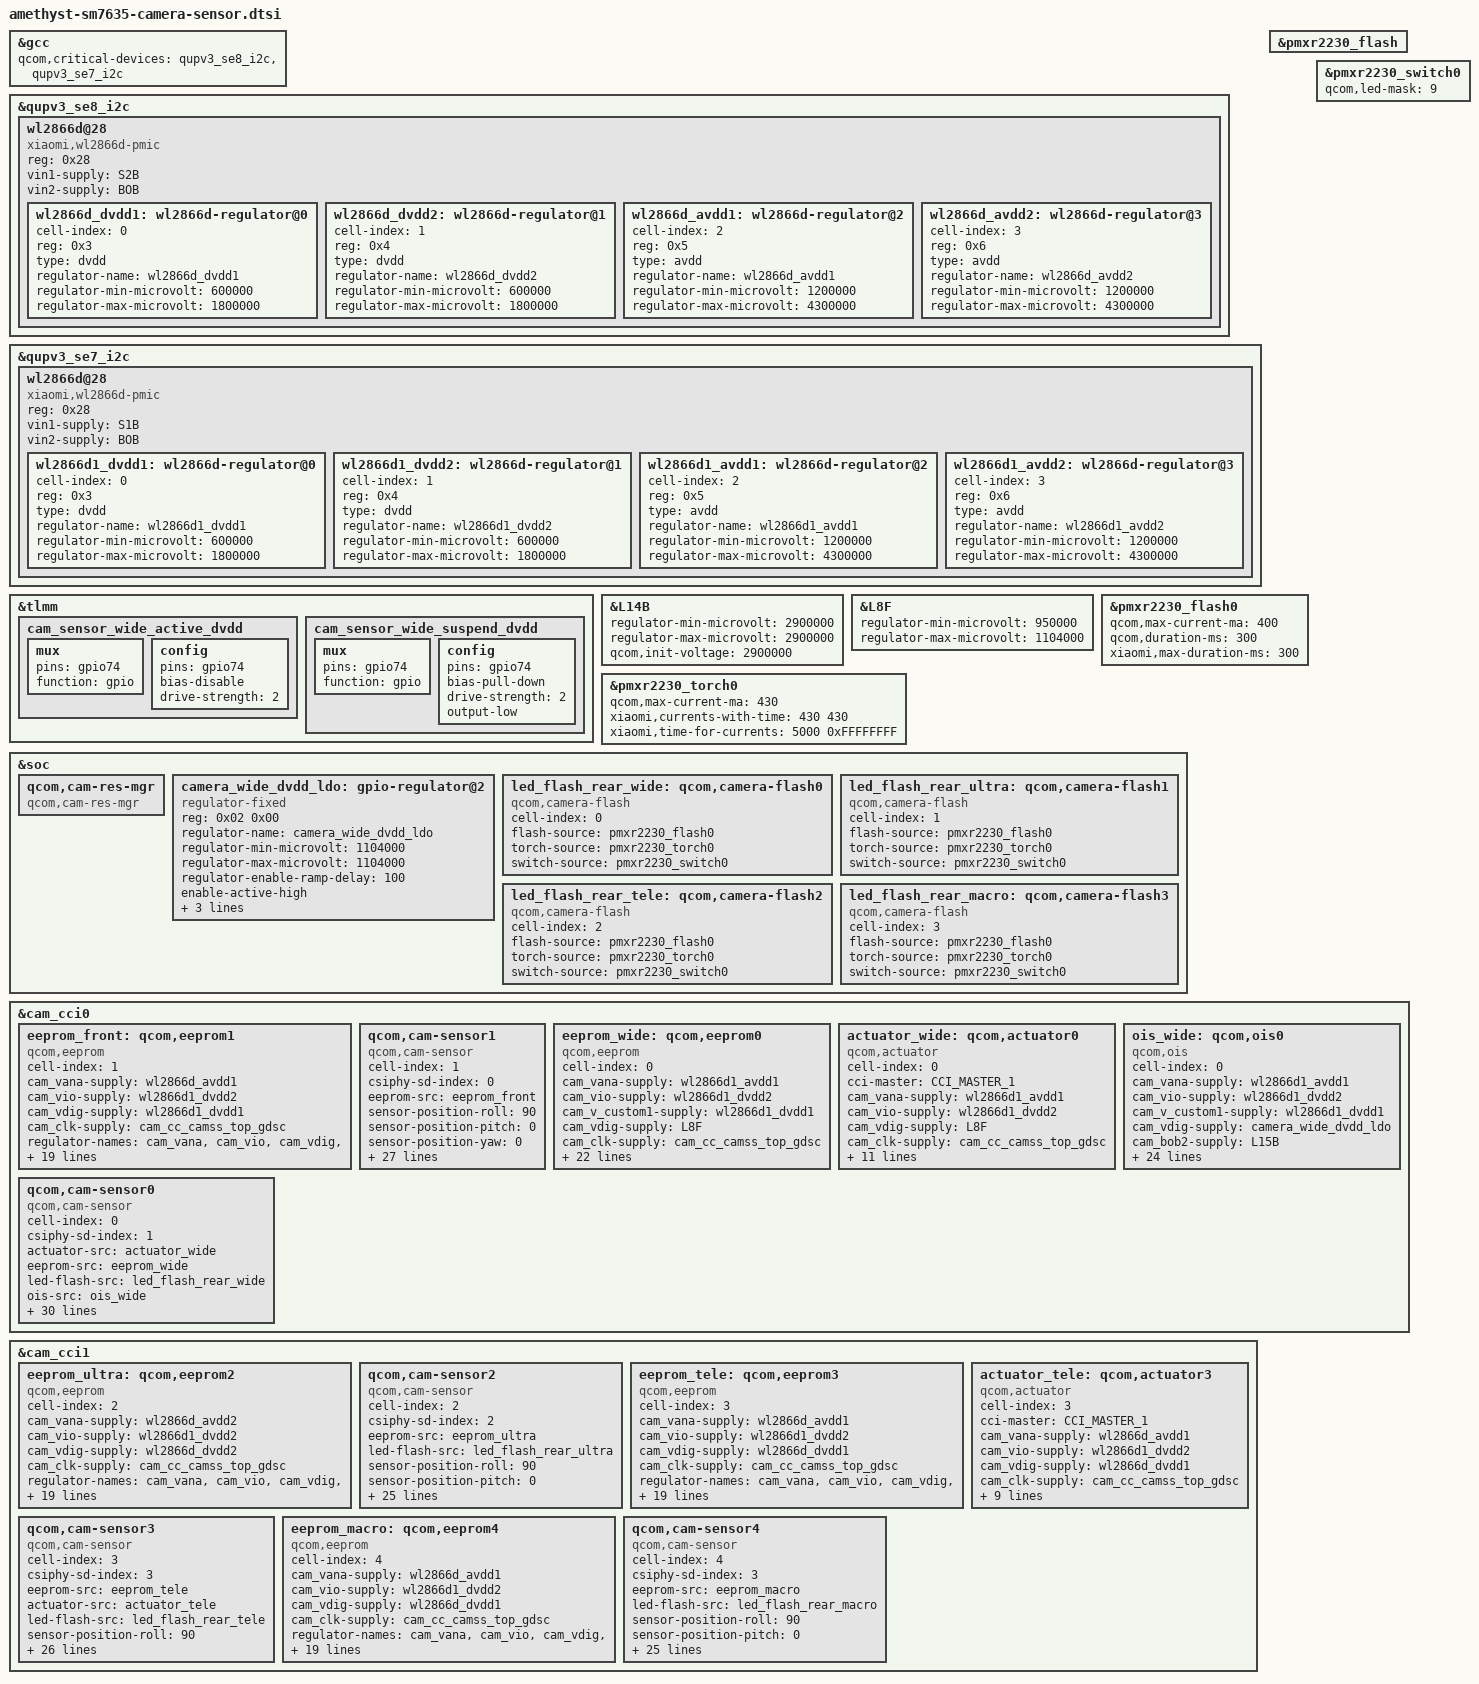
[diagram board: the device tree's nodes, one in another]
#include <dt-bindings/msm-camera.h>
&gcc {
	qcom,critical-devices = <&qupv3_se8_i2c &qupv3_se7_i2c>;
};
//bob
&qupv3_se8_i2c {
	#address-cells = <1>;
	#size-cells = <0>;
	status = "ok";

	wl2866d@28 {
		compatible = "xiaomi,wl2866d-pmic";
		reg = <0x28>;
		vin1-supply = <&S2B>;
		vin2-supply = <&BOB>;

		wl2866d_dvdd1: wl2866d-regulator@0 {
			cell-index = <0>;
			reg = /bits/ 8 <0x3>;
			type = "dvdd";
			regulator-name = "wl2866d_dvdd1";
			regulator-min-microvolt = <600000>;
			regulator-max-microvolt = <1800000>;
		};

		wl2866d_dvdd2: wl2866d-regulator@1 {
			cell-index = <1>;
			reg = /bits/ 8 <0x4>;
			type = "dvdd";
			regulator-name = "wl2866d_dvdd2";
			regulator-min-microvolt = <600000>;
			regulator-max-microvolt = <1800000>;
		};

		wl2866d_avdd1: wl2866d-regulator@2 {
			cell-index = <2>;
			reg = /bits/ 8 <0x5>;
			type = "avdd";
			regulator-name = "wl2866d_avdd1";
			regulator-min-microvolt = <1200000>;
			regulator-max-microvolt = <4300000>;
		};

		wl2866d_avdd2: wl2866d-regulator@3 {
			cell-index = <3>;
			reg = /bits/ 8 <0x6>;
			type = "avdd";
			regulator-name = "wl2866d_avdd2";
			regulator-min-microvolt = <1200000>;
			regulator-max-microvolt = <4300000>;
		};
	};
};
//hap
&qupv3_se7_i2c {
	#address-cells = <1>;
	#size-cells = <0>;
	status = "ok";

	wl2866d@28 {
		compatible = "xiaomi,wl2866d-pmic";
		reg = <0x28>;
		vin1-supply = <&S1B>;
		vin2-supply = <&BOB>;

		wl2866d1_dvdd1: wl2866d-regulator@0 {
			cell-index = <0>;
			reg = /bits/ 8 <0x3>;
			type = "dvdd";
			regulator-name = "wl2866d1_dvdd1";
			regulator-min-microvolt = <600000>;
			regulator-max-microvolt = <1800000>;
		};

		wl2866d1_dvdd2: wl2866d-regulator@1 {
			cell-index = <1>;
			reg = /bits/ 8 <0x4>;
			type = "dvdd";
			regulator-name = "wl2866d1_dvdd2";
			regulator-min-microvolt = <600000>;
			regulator-max-microvolt = <1800000>;
		};

		wl2866d1_avdd1: wl2866d-regulator@2 {
			cell-index = <2>;
			reg = /bits/ 8 <0x5>;
			type = "avdd";
			regulator-name = "wl2866d1_avdd1";
			regulator-min-microvolt = <1200000>;
			regulator-max-microvolt = <4300000>;
		};

		wl2866d1_avdd2: wl2866d-regulator@3 {
			cell-index = <3>;
			reg = /bits/ 8 <0x6>;
			type = "avdd";
			regulator-name = "wl2866d1_avdd2";
			regulator-min-microvolt = <1200000>;
			regulator-max-microvolt = <4300000>;
		};
	};
};

&tlmm {

	cam_sensor_wide_active_dvdd: cam_sensor_wide_active_dvdd {
		mux {
			pins = "gpio74";
			function = "gpio";
		};

		config {
			pins = "gpio74";
			bias-disable; /* No PULL */
			drive-strength = <2>; /* 2 MA */
		};
	};

	cam_sensor_wide_suspend_dvdd: cam_sensor_wide_suspend_dvdd {
		mux {
			pins = "gpio74";
			function = "gpio";
		};

		config {
			pins = "gpio74";
			bias-pull-down; /* PULL DOWN */
			drive-strength = <2>; /* 2 MA */
			output-low;
		};
	};
};

&L14B {
	regulator-min-microvolt = <2900000>;
	regulator-max-microvolt = <2900000>;
	qcom,init-voltage = <2900000>;
};

&L8F {
	regulator-min-microvolt = <950000>;
	regulator-max-microvolt = <1104000>;
};

&pmxr2230_flash {
	status = "ok";
};

&pmxr2230_flash0 {
	qcom,max-current-ma = <400>;
	qcom,duration-ms = <300>;
	xiaomi,max-duration-ms = <300>;
};

&pmxr2230_torch0{
	qcom,max-current-ma = <430>;
	xiaomi,currents-with-time = <430 430>;
	xiaomi,time-for-currents = <5000 0xFFFFFFFF>;  /* 0xFFFFFFFF means flash always on*/
};

&pmxr2230_switch0 {
	qcom,led-mask = <9>; // Channels 1 & 4
	// qcom,symmetry-en;
};

&soc {
	qcom,cam-res-mgr {
		compatible = "qcom,cam-res-mgr";
		status = "ok";
	};

	camera_wide_dvdd_ldo: gpio-regulator@2 {
		compatible = "regulator-fixed";
		reg = <0x02 0x00>;
		regulator-name = "camera_wide_dvdd_ldo";
		regulator-min-microvolt = <1104000>;
		regulator-max-microvolt = <1104000>;
		regulator-enable-ramp-delay = <100>;
		enable-active-high;
		gpio = <&tlmm 74 0>;
		pinctrl-names = "wide_dvdd_active", "wide_dvdd_suspend";
		pinctrl-0 = <&cam_sensor_wide_active_dvdd
					 &cam_sensor_wide_suspend_dvdd>;
	};

	led_flash_rear_wide: qcom,camera-flash0 {
		cell-index = <0>;
		compatible = "qcom,camera-flash";
		flash-source = <&pmxr2230_flash0 >;
		torch-source = <&pmxr2230_torch0 >;
		switch-source = <&pmxr2230_switch0>;
		status = "ok";
	};

	led_flash_rear_ultra: qcom,camera-flash1 {
		cell-index = <1>;
		compatible = "qcom,camera-flash";
		flash-source = <&pmxr2230_flash0 >;
		torch-source = <&pmxr2230_torch0 >;
		switch-source = <&pmxr2230_switch0>;
		status = "ok";
	};

	led_flash_rear_tele: qcom,camera-flash2 {
		cell-index = <2>;
		compatible = "qcom,camera-flash";
		flash-source = <&pmxr2230_flash0 >;
		torch-source = <&pmxr2230_torch0 >;
		switch-source = <&pmxr2230_switch0>;
		status = "ok";
	};

	led_flash_rear_macro: qcom,camera-flash3 {
		cell-index = <3>;
		compatible = "qcom,camera-flash";
		flash-source = <&pmxr2230_flash0 >;
		torch-source = <&pmxr2230_torch0 >;
		switch-source = <&pmxr2230_switch0>;
		status = "ok";
	};



};

&cam_cci0 {

	eeprom_front: qcom,eeprom1 {
		cell-index = <1>;
		compatible = "qcom,eeprom";
		cam_vana-supply = <&wl2866d_avdd1>;
		cam_vio-supply = <&wl2866d1_dvdd2>;
		cam_vdig-supply = <&wl2866d1_dvdd1>;
		cam_clk-supply = <&cam_cc_camss_top_gdsc>;
		regulator-names = "cam_vana", "cam_vio", "cam_vdig",
			"cam_clk";
		rgltr-cntrl-support;
		rgltr-min-voltage = <2800000 1800000 1200000 0>;
		rgltr-max-voltage = <2800000 1800000 1200000 0>;
		rgltr-load-current = <50000 50000 50000 0>;
		gpio-no-mux = <0>;
		pinctrl-names = "cam_default", "cam_suspend";
		pinctrl-0 = <&cam_sensor_mclk0_active
			&cam_sensor_active_rst0>;
		pinctrl-1 = <&cam_sensor_mclk0_suspend
			&cam_sensor_suspend_rst0>;
		gpios = <&tlmm 83 0>, <&tlmm 40 0>;
		gpio-reset = <1>;
		gpio-req-tbl-num = <0 1>;
		gpio-req-tbl-flags = <1 0>;
		gpio-req-tbl-label = "CAMIF_MCLK0", "CAM_RESET0";
		cci-master = <CCI_MASTER_0>;
		clocks = <&camcc CAM_CC_MCLK0_CLK>;
		clock-names = "cam_clk";
		clock-cntl-level = "nominal";
		clock-rates = <19200000>;
		status = "ok";
	};

// front sensor
	qcom,cam-sensor1 {
		cell-index = <1>;
		compatible = "qcom,cam-sensor";
		csiphy-sd-index = <0>;
		eeprom-src = <&eeprom_front>;
		sensor-position-roll = <90>;
		sensor-position-pitch = <0>;
		sensor-position-yaw = <0>;
		cam_vana-supply = <&wl2866d_avdd1>;
		cam_vio-supply = <&wl2866d1_dvdd2>;
		cam_vdig-supply = <&wl2866d1_dvdd1>;
		cam_v_custom2-supply = <&wl2866d_dvdd1>;
		cam_clk-supply = <&cam_cc_camss_top_gdsc>;
		regulator-names = "cam_vana", "cam_vio", "cam_vdig","cam_v_custom2",
			"cam_clk";
		rgltr-cntrl-support;
		rgltr-min-voltage = <2800000 1800000 1200000 1200000 0>;
		rgltr-max-voltage = <2800000 1800000 1800000 1200000 0>;
		rgltr-load-current = <50000 50000 50000 5000 0>;
		gpio-no-mux = <0>;
		pinctrl-names = "cam_default", "cam_suspend";
		pinctrl-0 = <&cam_sensor_mclk0_active
			&cam_sensor_active_rst0>;
		pinctrl-1 = <&cam_sensor_mclk0_suspend
			&cam_sensor_suspend_rst0>;
		gpios = <&tlmm 83 0>, <&tlmm 40 0>;
		gpio-reset = <1>;
		gpio-req-tbl-num = <0 1>;
		gpio-req-tbl-flags = <1 0>;
		gpio-req-tbl-label = "CAMIF_MCLK0", "CAM_RESET0";
		cci-master = <CCI_MASTER_0>;
		clocks = <&camcc CAM_CC_MCLK0_CLK>;
		clock-names = "cam_clk";
		clock-cntl-level = "nominal";
		clock-rates = <19200000>;
		status = "ok";
	};

	eeprom_wide: qcom,eeprom0 {
		cell-index = <0>;
		compatible = "qcom,eeprom";
		cam_vana-supply = <&wl2866d1_avdd1>;
		cam_vio-supply = <&wl2866d1_dvdd2>;
		cam_v_custom1-supply = <&wl2866d1_dvdd1>;
		cam_vdig-supply = <&L8F>;
		cam_clk-supply = <&cam_cc_camss_top_gdsc>;
		regulator-names = "cam_vana", "cam_vio", "cam_v_custom1",
			"cam_vdig", "cam_clk";
		rgltr-cntrl-support;
		rgltr-min-voltage = <2200000  1800000 1200000 950000  0 >;
		rgltr-max-voltage = <2800000  1800000 1800000 1104000 0 >;
		rgltr-load-current = <50000   50000  50000  50000  0 >;
		//use-shared-clk;
		gpio-no-mux = <0>;
		pinctrl-names = "cam_default", "cam_suspend";
		pinctrl-0 = <&cam_sensor_mclk1_active
			&cam_sensor_active_rst1>;
		pinctrl-1 = <&cam_sensor_mclk1_suspend
			&cam_sensor_suspend_rst1>;
		gpios = <&tlmm 84 0>, <&tlmm 41 0>;
		gpio-reset = <1>;
		gpio-req-tbl-num = <0 1>;
		gpio-req-tbl-flags = <1 0>;
		gpio-req-tbl-label = "CAMIF_MCLK1", "CAM_RESET1";
		cci-master = <CCI_MASTER_1>;
		clocks = <&camcc CAM_CC_MCLK1_CLK>;
		clock-names = "cam_clk";
		clock-cntl-level = "nominal";
		clock-rates = <19200000>;
		status = "ok";
	};

	// wide actuator
	actuator_wide: qcom,actuator0 {
		cell-index = <0>;
		compatible = "qcom,actuator";
		cci-master = <CCI_MASTER_1>;
		cam_vana-supply = <&wl2866d1_avdd1>;
		cam_vio-supply = <&wl2866d1_dvdd2>;
		cam_vdig-supply = <&L8F>;
		cam_clk-supply = <&cam_cc_camss_top_gdsc>;
		cam_vaf-supply = <&wl2866d1_avdd2>;
		cam_v_custom1-supply = <&wl2866d1_dvdd1>;
		regulator-names = "cam_vana", "cam_vio",
			"cam_vdig", "cam_clk", "cam_vaf", "cam_v_custom1";
		rgltr-cntrl-support;
		rgltr-min-voltage = <2200000 1800000 950000 0 3200000 1200000>;
		rgltr-max-voltage = <2800000 1800000 1104000 0 3200000 1800000>;
		rgltr-load-current = <50000 50000 50000 0 130000 50000>;
	};

	ois_wide: qcom,ois0 {
		cell-index = <0>;
		compatible = "qcom,ois";
		cam_vana-supply = <&wl2866d1_avdd1>;
		cam_vio-supply = <&wl2866d1_dvdd2>;
		cam_v_custom1-supply = <&wl2866d1_dvdd1>;
		cam_vdig-supply = <&camera_wide_dvdd_ldo>;
		cam_bob2-supply = <&L15B>;
		cam_clk-supply = <&cam_cc_camss_top_gdsc>;
		//cam_vaf-supply = <&wl2866d_avdd2>;
		regulator-names = "cam_vana", "cam_vio", "cam_v_custom1", "cam_vdig", "cam_bob2", "cam_clk";
		rgltr-cntrl-support;
		rgltr-min-voltage = <2200000  1800000  1200000 950000 3100000 0 >;
		rgltr-max-voltage = <2800000  1800000  1800000 1104000 3100000 0 >;
		rgltr-load-current = <50000   50000   50000  50000 50000 0 >;
		//use-shared-clk;
		gpio-no-mux = <0>;
		pinctrl-names = "cam_default", "cam_suspend";
		pinctrl-0 = <&cam_sensor_mclk1_active
			&cam_sensor_active_rst1>;
		pinctrl-1 = <&cam_sensor_mclk1_suspend
			&cam_sensor_suspend_rst1>;
		gpios = <&tlmm 84 0>, <&tlmm 41 0>;
		gpio-reset = <1>;
		gpio-req-tbl-num = <0 1>;
		gpio-req-tbl-flags = <1 0>;
		gpio-req-tbl-label = "CAMIF_MCLK1", "CAM_RESET1";
		cci-master = <CCI_MASTER_1>;
		clocks = <&camcc CAM_CC_MCLK1_CLK>;
		clock-names = "cam_clk";
		clock-cntl-level = "nominal";
		clock-rates = <19200000>;
		status = "ok";
	};

	// wide sensor
	qcom,cam-sensor0 {
		cell-index = <0>;
		compatible = "qcom,cam-sensor";
		csiphy-sd-index = <1>;
		actuator-src = <&actuator_wide>;
		eeprom-src = <&eeprom_wide>;
		led-flash-src = <&led_flash_rear_wide>;
		ois-src = <&ois_wide>;
		sensor-position-roll = <90>;
		sensor-position-pitch = <0>;
		sensor-position-yaw = <180>;
		cam_vana-supply = <&wl2866d1_avdd1>;
		cam_vio-supply = <&wl2866d1_dvdd2>;
		cam_v_custom1-supply = <&wl2866d1_dvdd1>;
		cam_vdig-supply = <&L8F>;
		//cam_v_custom1-supply = <&L16B>;
		//cam_vaf-supply = <&wl2866d_avdd2>;
		cam_clk-supply = <&cam_cc_camss_top_gdsc>;
		regulator-names = "cam_vana", "cam_vio","cam_v_custom1",
			"cam_vdig", "cam_clk";
		rgltr-cntrl-support;
		rgltr-min-voltage = <2200000  1800000 1200000 950000  0>;
		rgltr-max-voltage = <2800000  1800000 1800000 1104000 0>;
		rgltr-load-current = <50000   50000   50000 50000  0>;
		//use-shared-clk;
		gpio-no-mux = <0>;
		pinctrl-names = "cam_default", "cam_suspend";
		pinctrl-0 = <&cam_sensor_mclk1_active
			&cam_sensor_active_rst1>;
		pinctrl-1 = <&cam_sensor_mclk1_suspend
			&cam_sensor_suspend_rst1>;
		gpios = <&tlmm 84 0>, <&tlmm 41 0>;
		gpio-reset = <1>;
		gpio-req-tbl-num = <0 1>;
		gpio-req-tbl-flags = <1 0>;
		gpio-req-tbl-label = "CAMIF_MCLK1", "CAM_RESET1";
		cci-master = <CCI_MASTER_1>;
		clocks = <&camcc CAM_CC_MCLK1_CLK>;
		clock-names = "cam_clk";
		clock-cntl-level = "nominal";
		clock-rates = <19200000>;
		status = "ok";
	};

};

&cam_cci1 {

	eeprom_ultra: qcom,eeprom2 {
		cell-index = <2>;
		compatible = "qcom,eeprom";
		cam_vana-supply = <&wl2866d_avdd2>;
		cam_vio-supply = <&wl2866d1_dvdd2>;
		cam_vdig-supply = <&wl2866d_dvdd2>;
		cam_clk-supply = <&cam_cc_camss_top_gdsc>;
		regulator-names = "cam_vana", "cam_vio", "cam_vdig",
			 "cam_clk";
		rgltr-cntrl-support;
		rgltr-min-voltage = <2800000 1800000 1200000 0>;
		rgltr-max-voltage = <2800000 1800000 1200000 0>;
		rgltr-load-current = <50000 50000 50000 0>;
		gpio-no-mux = <0>;
		pinctrl-names = "cam_default", "cam_suspend";
		pinctrl-0 = <&cam_sensor_mclk2_active
			&cam_sensor_active_rst2>;
		pinctrl-1 = <&cam_sensor_mclk2_suspend
			&cam_sensor_suspend_rst2>;
		gpios = <&tlmm 85 0>, <&tlmm 42 0>;
		gpio-reset = <1>;
		gpio-req-tbl-num = <0 1>;
		gpio-req-tbl-flags = <1 0>;
		gpio-req-tbl-label = "CAMIF_MCLK2", "CAM_RESET2";
		cci-master = <CCI_MASTER_0>;
		clocks = <&camcc CAM_CC_MCLK2_CLK>;
		clock-names = "cam_clk";
		clock-cntl-level = "nominal";
		clock-rates = <19200000>;
		status = "ok";
	};

	// ultra sensor
	qcom,cam-sensor2 {
		cell-index = <2>;
		compatible = "qcom,cam-sensor";
		csiphy-sd-index = <2>;
		eeprom-src = <&eeprom_ultra>;
		led-flash-src = <&led_flash_rear_ultra>;
		sensor-position-roll = <90>;
		sensor-position-pitch = <0>;
		sensor-position-yaw = <180>;
		cam_vana-supply = <&wl2866d_avdd2>;
		cam_vio-supply = <&wl2866d1_dvdd2>;
		cam_vdig-supply = <&wl2866d_dvdd2>;
		cam_clk-supply = <&cam_cc_camss_top_gdsc>;
		regulator-names = "cam_vana", "cam_vio", "cam_vdig",
			 "cam_clk";
		rgltr-cntrl-support;
		rgltr-min-voltage = <2800000 1800000 1200000 0>;
		rgltr-max-voltage = <2800000 1800000 1200000 0>;
		rgltr-load-current = <50000 50000 50000 0>;
		gpio-no-mux = <0>;
		pinctrl-names = "cam_default", "cam_suspend";
		pinctrl-0 = <&cam_sensor_mclk2_active
			&cam_sensor_active_rst2>;
		pinctrl-1 = <&cam_sensor_mclk2_suspend
			&cam_sensor_suspend_rst2>;
		gpios = <&tlmm 85 0>, <&tlmm 42 0>;
		gpio-reset = <1>;
		gpio-req-tbl-num = <0 1>;
		gpio-req-tbl-flags = <1 0>;
		gpio-req-tbl-label = "CAMIF_MCLK2", "CAM_RESET2";
		cci-master = <CCI_MASTER_0>;
		clocks = <&camcc CAM_CC_MCLK2_CLK>;
		clock-names = "cam_clk";
		clock-cntl-level = "nominal";
		clock-rates = <19200000>;
		status = "ok";
	};

	eeprom_tele: qcom,eeprom3 {
		cell-index = <3>;
		compatible = "qcom,eeprom";
		cam_vana-supply = <&wl2866d_avdd1>;
		cam_vio-supply = <&wl2866d1_dvdd2>;
		cam_vdig-supply = <&wl2866d_dvdd1>;
		cam_clk-supply = <&cam_cc_camss_top_gdsc>;
		regulator-names = "cam_vana", "cam_vio", "cam_vdig", "cam_clk";
		rgltr-cntrl-support;
		rgltr-min-voltage = <2800000 1800000 1100000 0>;
		rgltr-max-voltage = <2800000 1800000 1104000 0>;
		rgltr-load-current = <50000 50000 50000 0>;
		gpio-no-mux = <0>;
		pinctrl-names = "cam_default", "cam_suspend";
		pinctrl-0 = <&cam_sensor_mclk3_active
			&cam_sensor_active_rst3>;
		pinctrl-1 = <&cam_sensor_mclk3_suspend
			&cam_sensor_suspend_rst3>;
		gpios = <&tlmm 86 0>, <&tlmm 43 0>;
		gpio-reset = <1>;
		gpio-req-tbl-num = <0 1>;
		gpio-req-tbl-flags = <1 0>;
		gpio-req-tbl-label = "CAMIF_MCLK3", "CAM_RESET3";
		cci-master = <CCI_MASTER_1>;
		clocks = <&camcc CAM_CC_MCLK3_CLK>;
		clock-names = "cam_clk";
		clock-cntl-level = "nominal";
		clock-rates = <19200000>;
		status = "ok";
	};

	actuator_tele: qcom,actuator3 {
		cell-index = <3>;
		compatible = "qcom,actuator";
		cci-master = <CCI_MASTER_1>;
		cam_vana-supply = <&wl2866d_avdd1>;
		cam_vio-supply = <&wl2866d1_dvdd2>;
		cam_vdig-supply = <&wl2866d_dvdd1>;
		cam_clk-supply = <&cam_cc_camss_top_gdsc>;
		cam_vaf-supply = <&L14B>;
		regulator-names = "cam_vana", "cam_vio", "cam_vdig", "cam_clk", "cam_vaf";
		rgltr-cntrl-support;
		rgltr-min-voltage = <2800000 1800000 1100000 0 2900000>;
		rgltr-max-voltage = <2800000 1800000 1104000 0 2900000>;
		rgltr-load-current = <50000 50000 50000 0 130000>;
	};

	// tele sensor
	qcom,cam-sensor3 {
		cell-index = <3>;
		compatible = "qcom,cam-sensor";
		csiphy-sd-index = <3>;
		eeprom-src = <&eeprom_tele>;
		actuator-src = <&actuator_tele>;
		led-flash-src = <&led_flash_rear_tele>;
		sensor-position-roll = <90>;
		sensor-position-pitch = <0>;
		sensor-position-yaw = <180>;
		cam_vana-supply = <&wl2866d_avdd1>;
		cam_vio-supply = <&wl2866d1_dvdd2>;
		cam_vdig-supply = <&wl2866d_dvdd1>;
		cam_clk-supply = <&cam_cc_camss_top_gdsc>;
		regulator-names = "cam_vana", "cam_vio", "cam_vdig", "cam_clk";
		rgltr-cntrl-support;
		rgltr-min-voltage = <2800000 1800000 1100000 0>;
		rgltr-max-voltage = <2800000 1800000 1104000 0>;
		rgltr-load-current = <50000 50000 50000 0>;
		gpio-no-mux = <0>;
		pinctrl-names = "cam_default", "cam_suspend";
		pinctrl-0 = <&cam_sensor_mclk3_active
			&cam_sensor_active_rst3>;
		pinctrl-1 = <&cam_sensor_mclk3_suspend
			&cam_sensor_suspend_rst3>;
		gpios = <&tlmm 86 0>, <&tlmm 43 0>;
		gpio-reset = <1>;
		gpio-req-tbl-num = <0 1>;
		gpio-req-tbl-flags = <1 0>;
		gpio-req-tbl-label = "CAMIF_MCLK3", "CAM_RESET3";
		cci-master = <CCI_MASTER_1>;
		clocks = <&camcc CAM_CC_MCLK3_CLK>;
		clock-names = "cam_clk";
		clock-cntl-level = "nominal";
		clock-rates = <19200000>;
		status = "ok";
	};

	eeprom_macro: qcom,eeprom4 {
		cell-index = <4>;
		compatible = "qcom,eeprom";
		cam_vana-supply = <&wl2866d_avdd1>;
		cam_vio-supply = <&wl2866d1_dvdd2>;
		cam_vdig-supply = <&wl2866d_dvdd1>;
		cam_clk-supply = <&cam_cc_camss_top_gdsc>;
		regulator-names = "cam_vana", "cam_vio", "cam_vdig", "cam_clk";
		rgltr-cntrl-support;
		rgltr-min-voltage = <2800000 1800000 1100000 0>;
		rgltr-max-voltage = <2800000 1800000 1104000 0>;
		rgltr-load-current = <50000 50000 50000 0>;
		gpio-no-mux = <0>;
		pinctrl-names = "cam_default", "cam_suspend";
		pinctrl-0 = <&cam_sensor_mclk3_active
			&cam_sensor_active_rst3>;
		pinctrl-1 = <&cam_sensor_mclk3_suspend
			&cam_sensor_suspend_rst3>;
		gpios = <&tlmm 86 0>, <&tlmm 43 0>;
		gpio-reset = <1>;
		gpio-req-tbl-num = <0 1>;
		gpio-req-tbl-flags = <1 0>;
		gpio-req-tbl-label = "CAMIF_MCLK3", "CAM_RESET3";
		cci-master = <CCI_MASTER_1>;
		clocks = <&camcc CAM_CC_MCLK3_CLK>;
		clock-names = "cam_clk";
		clock-cntl-level = "nominal";
		clock-rates = <19200000>;
		status = "ok";
	};

	// macro sensor
	qcom,cam-sensor4 {
		cell-index = <4>;
		compatible = "qcom,cam-sensor";
		csiphy-sd-index = <3>;
		eeprom-src = <&eeprom_macro>;
		led-flash-src = <&led_flash_rear_macro>;
		sensor-position-roll = <90>;
		sensor-position-pitch = <0>;
		sensor-position-yaw = <180>;
		cam_vana-supply = <&wl2866d_avdd1>;
		cam_vio-supply = <&wl2866d1_dvdd2>;
		cam_vdig-supply = <&wl2866d_dvdd1>;
		cam_clk-supply = <&cam_cc_camss_top_gdsc>;
		regulator-names = "cam_vana", "cam_vio", "cam_vdig", "cam_clk";
		rgltr-cntrl-support;
		rgltr-min-voltage = <2800000 1800000 1100000 0>;
		rgltr-max-voltage = <2800000 1800000 1104000 0>;
		rgltr-load-current = <50000 50000 5000 0>;
		gpio-no-mux = <0>;
		pinctrl-names = "cam_default", "cam_suspend";
		pinctrl-0 = <&cam_sensor_mclk3_active
			&cam_sensor_active_rst3>;
		pinctrl-1 = <&cam_sensor_mclk3_suspend
			&cam_sensor_suspend_rst3>;
		gpios = <&tlmm 86 0>, <&tlmm 43 0>;
		gpio-reset = <1>;
		gpio-req-tbl-num = <0 1>;
		gpio-req-tbl-flags = <1 0>;
		gpio-req-tbl-label = "CAMIF_MCLK3", "CAM_RESET3";
		cci-master = <CCI_MASTER_1>;
		clocks = <&camcc CAM_CC_MCLK3_CLK>;
		clock-names = "cam_clk";
		clock-cntl-level = "nominal";
		clock-rates = <19200000>;
		status = "ok";
	};

};
